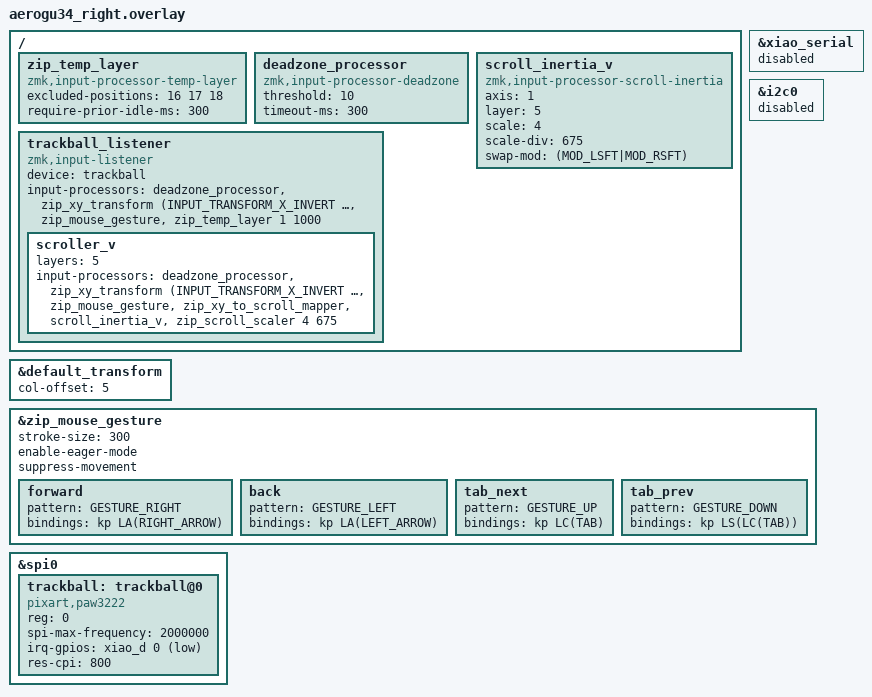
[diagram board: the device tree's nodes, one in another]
#include "aerogu34.dtsi"
#include <behaviors.dtsi>
#include <dt-bindings/zmk/input_transform.h>
#include <dt-bindings/zmk/modifiers.h>
#include <mouse-gesture.dtsi>

&default_transform {
    col-offset = <5>;
};

&xiao_serial { status = "disabled"; };
&i2c0 { status = "disabled"; };

/* マウスジェスチャー設定 */
&zip_mouse_gesture {
    stroke-size = <300>;
    enable-eager-mode;
    suppress-movement;

    forward {
        pattern = <GESTURE_RIGHT>;
        bindings = <&kp LA(RIGHT_ARROW)>;
    };

    back {
        pattern = <GESTURE_LEFT>;
        bindings = <&kp LA(LEFT_ARROW)>;
    };

    tab_next {
        pattern = <GESTURE_UP>;
        bindings = <&kp LC(TAB)>;
    };

    tab_prev {
        pattern = <GESTURE_DOWN>;
        bindings = <&kp LS(LC(TAB))>;
    };
};

/ {
    /* --- 新規ノード定義はルート / 配下に記述 --- */
    
    /* AML Auto Mouse Layer プロセッサ */
    zip_temp_layer: zip_temp_layer {
        compatible = "zmk,input-processor-temp-layer";
        #input-processor-cells = <2>;
        excluded-positions = <16 17 18>;
        require-prior-idle-ms = <300>;
    };

    deadzone_processor: deadzone_processor {
        compatible = "zmk,input-processor-deadzone";
        #input-processor-cells = <0>;
        threshold = <10>;
        timeout-ms = <300>;
    };

    /* SCROLLレイヤー用 慣性スクロール */
    scroll_inertia_v: scroll_inertia_v {
        compatible = "zmk,input-processor-scroll-inertia";
        #input-processor-cells = <0>;

        axis  = <1>;
        layer = <5>;

        scale     = <4>;
        scale-div = <675>;

        swap-mod = <(MOD_LSFT|MOD_RSFT)>;
    };

    trackball_listener: trackball_listener {
        compatible = "zmk,input-listener";
        device = <&trackball>;

        /* 通常時のインプットプロセッサ・チェーン */
        input-processors = <&deadzone_processor
                            &zip_xy_transform (INPUT_TRANSFORM_X_INVERT | INPUT_TRANSFORM_Y_INVERT)
                            &zip_mouse_gesture
                            &zip_temp_layer 1 1000>;

        /* SCROLLレイヤー (Index 5) 適用時 */
        scroller_v {
            layers = <5>;
            input-processors = <&deadzone_processor
                                &zip_xy_transform (INPUT_TRANSFORM_X_INVERT | INPUT_TRANSFORM_Y_INVERT)
                                &zip_mouse_gesture
                                &zip_xy_to_scroll_mapper
                                &scroll_inertia_v
                                &zip_scroll_scaler 4 675>;
        };
    };
};

&spi0 {
    status = "okay";

    trackball: trackball@0 {
        status = "okay";
        compatible = "pixart,paw3222";
        reg = <0>;
        spi-max-frequency = <2000000>;
        irq-gpios = <&xiao_d 0 (GPIO_ACTIVE_LOW | GPIO_PULL_UP)>;
        res-cpi = <800>;
    };
};
